AUTOSAR XML (schema 4-0-3)
standard types defined: Boolean, UInt16, UInt32, UInt8
package /AUTOSAR_Platform/DataConstrs
  range DC_Boolean: raw 0..1
  range DC_UInt16: raw 0..65535
  range DC_UInt8: raw 0..255
package /PATAC/MSM/ComponentTypes
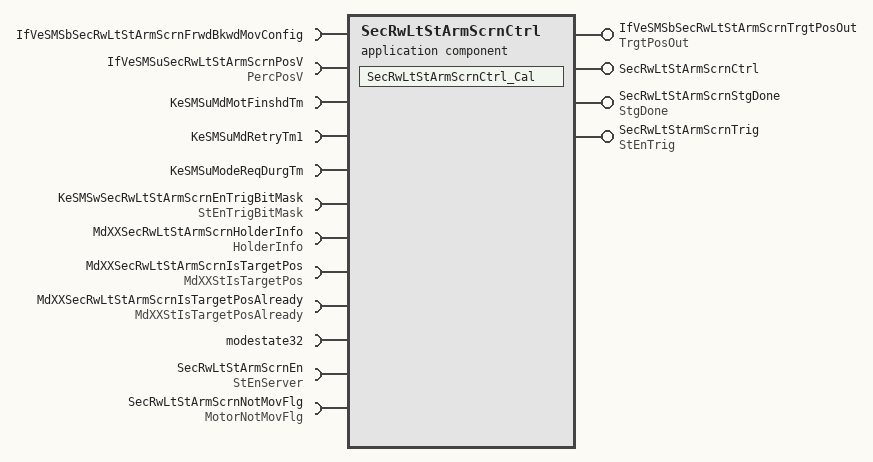
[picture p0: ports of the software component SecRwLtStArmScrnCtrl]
  application sw component type SecRwLtStArmScrnCtrl
    4 x provide port:
      IfVeSMSbSecRwLtStArmScrnTrgtPosOut: nonqueued-sender-com-spec{data-element=TrgtPosOut/Val, init-value=0}, provided-interface=TrgtPosOut
      SecRwLtStArmScrnCtrl: server-com-spec{operation=Cal, queue-length=1}, provided-interface=SecRwLtStArmScrnCtrl
      SecRwLtStArmScrnStgDone: nonqueued-sender-com-spec{data-element=StgDone/Val, init-value=0}, provided-interface=StgDone
      SecRwLtStArmScrnTrig: nonqueued-sender-com-spec{data-element=StEnTrig/Val, init-value=0}, provided-interface=StEnTrig
    12 x require port:
      IfVeSMSbSecRwLtStArmScrnFrwdBkwdMovConfig: nonqueued-receiver-com-spec{data-element=IfVeSMSbSecRwLtStArmScrnFrwdBkwdMovConfig/Val, filter=data-filter-type=ALWAYS, init-value=0}, required-interface=IfVeSMSbSecRwLtStArmScrnFrwdBkwdMovConfig
      IfVeSMSuSecRwLtStArmScrnPosV: nonqueued-receiver-com-spec{data-element=PercPosV/Val, filter=data-filter-type=ALWAYS, init-value=0}, required-interface=PercPosV
      KeSMSuMdMotFinshdTm: parameter-require-com-spec{init-value=0, parameter=KeSMSuMdMotFinshdTm/Val}, required-interface=KeSMSuMdMotFinshdTm
      KeSMSuMdRetryTm1: parameter-require-com-spec{init-value=0, parameter=KeSMSuMdRetryTm1/Val}, required-interface=KeSMSuMdRetryTm1
      KeSMSuModeReqDurgTm: parameter-require-com-spec{init-value=0, parameter=KeSMSuModeReqDurgTm/Val}, required-interface=KeSMSuModeReqDurgTm
      KeSMSwSecRwLtStArmScrnEnTrigBitMask: parameter-require-com-spec{init-value=6153, parameter=StEnTrigBitMask/Val}, required-interface=StEnTrigBitMask
      MdXXSecRwLtStArmScrnHolderInfo: nonqueued-receiver-com-spec{data-element=HolderInfo/Val, filter=data-filter-type=ALWAYS, init-value=0}, required-interface=HolderInfo
      MdXXSecRwLtStArmScrnIsTargetPos: nonqueued-receiver-com-spec{data-element=MdXXStIsTargetPos/Val, filter=data-filter-type=ALWAYS, init-value=0}, required-interface=MdXXStIsTargetPos
      MdXXSecRwLtStArmScrnIsTargetPosAlready: nonqueued-receiver-com-spec{data-element=MdXXStIsTargetPosAlready/Val, filter=data-filter-type=ALWAYS, init-value=0}, required-interface=MdXXStIsTargetPosAlready
      modestate32: nonqueued-receiver-com-spec{data-element=modestate32/Val, filter=data-filter-type=ALWAYS, init-value=0}, required-interface=modestate32
      SecRwLtStArmScrnEn: required-com-specs=[Clear, Get, Set], required-interface=StEnServer
      SecRwLtStArmScrnNotMovFlg: nonqueued-receiver-com-spec{data-element=MotorNotMovFlg/Val, filter=data-filter-type=ALWAYS, init-value=0}, required-interface=MotorNotMovFlg
    behavior SecRwLtStArmScrnCtrl_InternalBehavior
      operation invoked event OIT_SecRwLtStArmScrnCtrl_Cal_SecRwLtStArmScrnCtrl_Cal: start-on-event=SecRwLtStArmScrnCtrl_Cal, operation=SecRwLtStArmScrnCtrl.Cal
      runnable SecRwLtStArmScrnCtrl_Cal
        data-receive-point-by-arguments:
          7 x access:
            REC_IfVeSMSbSecRwLtStArmScrnFrwdBkwdMovConfig_Val: accessed-variable=IfVeSMSbSecRwLtStArmScrnFrwdBkwdMovConfig.Val
            REC_IfVeSMSuSecRwLtStArmScrnPosV_Val: accessed-variable=IfVeSMSuSecRwLtStArmScrnPosV.Val
            REC_MdXXSecRwLtStArmScrnHolderInfo_Val: accessed-variable=MdXXSecRwLtStArmScrnHolderInfo.Val
            REC_MdXXSecRwLtStArmScrnIsTargetPos_Val: accessed-variable=MdXXSecRwLtStArmScrnIsTargetPos.Val
            REC_MdXXSecRwLtStArmScrnIsTargetPosAlready_Val: accessed-variable=MdXXSecRwLtStArmScrnIsTargetPosAlready.Val
            REC_modestate32_Val: accessed-variable=modestate32.Val
            REC_SecRwLtStArmScrnNotMovFlg_Val: accessed-variable=SecRwLtStArmScrnNotMovFlg.Val
        data-send-points:
          access SEND_IfVeSMSbSecRwLtStArmScrnTrgtPosOut_Val: accessed-variable=IfVeSMSbSecRwLtStArmScrnTrgtPosOut.Val
          access SEND_SecRwLtStArmScrnStgDone_Val: accessed-variable=SecRwLtStArmScrnStgDone.Val
          access SEND_SecRwLtStArmScrnTrig_Val: accessed-variable=SecRwLtStArmScrnTrig.Val
        4 x parameter access:
          PA_KeSMSuMdMotFinshdTm_Val: accessed-parameter=KeSMSuMdMotFinshdTm.Val
          PA_KeSMSuMdRetryTm1_Val: accessed-parameter=KeSMSuMdRetryTm1.Val
          PA_KeSMSuModeReqDurgTm_Val: accessed-parameter=KeSMSuModeReqDurgTm.Val
          PA_KeSMSwSecRwLtStArmScrnEnTrigBitMask_Val: accessed-parameter=KeSMSwSecRwLtStArmScrnEnTrigBitMask.Val
        sync call SC_SecRwLtStArmScrnEn_Get: operation=SecRwLtStArmScrnEn.Get, timeout=0
  swc implementation SecRwLtStArmScrnCtrl_Implementation: behavior=SecRwLtStArmScrnCtrl_InternalBehavior
    code-descriptors:
      code Default: artifact-descriptors=autosar-engineering-object={short-label=Default, category=SWSRC}
package /PATAC/MSM/ModeAdjust/CalPortInterface
  parameter interface KeSMSuMdMotFinshdTm
    parameter data prototype Val: sw-calibration-access=READ-WRITE, type=UInt16
  parameter interface KeSMSuModeReqDurgTm
    parameter data prototype Val: sw-calibration-access=READ-WRITE, type=UInt16
  parameter interface StEnTrigBitMask
    parameter data prototype Val: sw-calibration-access=READ-WRITE, type=UInt32
package /PATAC/MSM/ModeAdjust/PortInterface
  client server interface SecRwLtStArmScrnCtrl
    operation Cal
  client server interface StEnServer
    operation Clear
      arg data: type=UInt8, direction=IN, server-argument-impl-policy=USE-ARGUMENT-TYPE
    operation Get
      arg data: type=UInt32, direction=OUT, server-argument-impl-policy=USE-ARGUMENT-TYPE
    operation Set
      arg data: type=UInt8, direction=IN, server-argument-impl-policy=USE-ARGUMENT-TYPE
  10 x sender receiver interface:
    HolderInfo: invalidation-policy{data-element=HolderInfo/Val, handle-invalid=DONT-INVALIDATE}
      data Val: type=UInt32
    IfVeSMSbSecRwLtStArmScrnFrwdBkwdMovConfig: invalidation-policy{data-element=IfVeSMSbSecRwLtStArmScrnFrwdBkwdMovConfig/Val, handle-invalid=DONT-INVALIDATE}
      data Val: type=Boolean
    MdXXStIsTargetPos: invalidation-policy{data-element=MdXXStIsTargetPos/Val, handle-invalid=DONT-INVALIDATE}
      data Val: type=UInt32
    MdXXStIsTargetPosAlready: invalidation-policy{data-element=MdXXStIsTargetPosAlready/Val, handle-invalid=DONT-INVALIDATE}
      data Val: type=UInt32
    modestate32: invalidation-policy{data-element=modestate32/Val, handle-invalid=DONT-INVALIDATE}
      data Val: type=UInt32
    MotorNotMovFlg: invalidation-policy{data-element=MotorNotMovFlg/Val, handle-invalid=DONT-INVALIDATE}
      data Val: type=Boolean
    PercPosV: invalidation-policy{data-element=PercPosV/Val, handle-invalid=DONT-INVALIDATE}
      data Val: type=Boolean
    StEnTrig: invalidation-policy{data-element=StEnTrig/Val, handle-invalid=DONT-INVALIDATE}
      data Val: type=Boolean
    StgDone: invalidation-policy{data-element=StgDone/Val, handle-invalid=DONT-INVALIDATE}
      data Val: type=Boolean
    TrgtPosOut: invalidation-policy{data-element=TrgtPosOut/Val, handle-invalid=DONT-INVALIDATE}
      data Val: type=Boolean
package /PATAC/MSM/PortInterfaces
  parameter interface KeSMSuMdRetryTm1
    parameter data prototype Val: sw-calibration-access=READ-WRITE, type=UInt8
